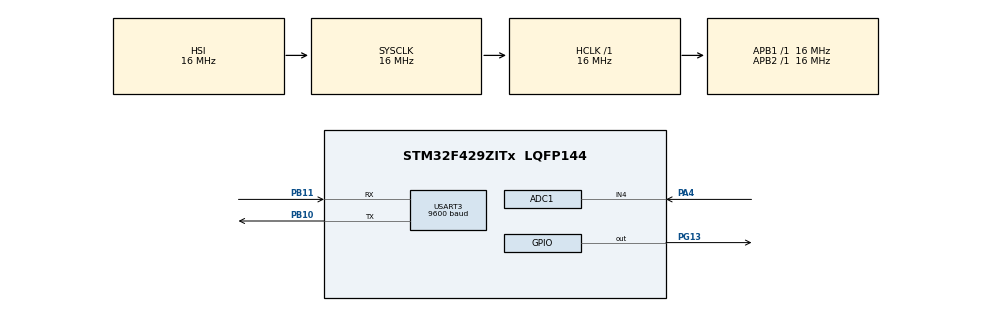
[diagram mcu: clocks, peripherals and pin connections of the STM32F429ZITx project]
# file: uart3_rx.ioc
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ADC1.Channel-0\#ChannelRegularConversion=ADC_CHANNEL_4
ADC1.ContinuousConvMode=ENABLE
ADC1.NbrOfConversionFlag=1
ADC1.Rank-0\#ChannelRegularConversion=1
ADC1.SamplingTime-0\#ChannelRegularConversion=ADC_SAMPLETIME_3CYCLES
ADC1.master=1
Mcu.Family=STM32F4
Mcu.Name=STM32F429ZITx
Mcu.Package=LQFP144
NVIC.PriorityGroup=NVIC_PRIORITYGROUP_4
NVIC.USART3_IRQn=true\:0\:0\:false\:false\:true\:true\:true\:true
PA13.Mode=Serial_Wire
PA13.Signal=SYS_JTMS-SWDIO
PA14.Mode=Serial_Wire
PA14.Signal=SYS_JTCK-SWCLK
PA4.Signal=ADCx_IN4
PB10.Mode=Asynchronous
PB10.Signal=USART3_TX
PB11.Mode=Asynchronous
PB11.Signal=USART3_RX
PG13.Signal=GPIO_Output
PH0/OSC_IN.Mode=HSE-External-Oscillator
PH0/OSC_IN.Signal=RCC_OSC_IN
PH1/OSC_OUT.Mode=HSE-External-Oscillator
PH1/OSC_OUT.Signal=RCC_OSC_OUT
ProjectManager.HeapSize=0x200
ProjectManager.StackSize=0x400
ProjectManager.TargetToolchain=STM32CubeIDE
RCC.AHBFreq_Value=16000000
RCC.APB1Freq_Value=16000000
RCC.APB2Freq_Value=16000000
RCC.CortexFreq_Value=16000000
RCC.HSE_VALUE=25000000
RCC.HSI_VALUE=16000000
RCC.LSE_VALUE=32768
RCC.SYSCLKFreq_VALUE=16000000
RCC.VCOOutputFreq_Value=192000000
SH.ADCx_IN4.0=ADC1_IN4,IN4
USART3.BaudRate=9600
USART3.VirtualMode=VM_ASYNC
board=custom

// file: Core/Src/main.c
/* USER CODE BEGIN Header */
/**
  ******************************************************************************
  * @file           : main.c
  * @brief          : Main program body
  ******************************************************************************
  * @attention
  *
  * Copyright (c) 2024 STMicroelectronics.
  * All rights reserved.
  *
  * This software is licensed under terms that can be found in the LICENSE file
  * in the root directory of this software component.
  * If no LICENSE file comes with this software, it is provided AS-IS.
  *
  ******************************************************************************
  */
/* USER CODE END Header */
#include "main.h"
#include "adc.h"
#include "usart.h"
#include "gpio.h"

/* USER CODE BEGIN Includes */
#include <stdio.h>
#include <string.h>  // 추가: strlen() 함수 사용을 위한 헤더 파일 포함
/* USER CODE END Includes */

/* USER CODE BEGIN PV */
char buffer[10];
/* USER CODE END PV */

void SystemClock_Config(void);

int main(void)
{

  /* MCU Configuration--------------------------------------------------------*/

  /* Reset of all peripherals, Initializes the Flash interface and the Systick. */
  HAL_Init();

  /* Configure the system clock */
  SystemClock_Config();

  /* Initialize all configured peripherals */
  MX_GPIO_Init();
  MX_USART3_UART_Init();
  MX_ADC1_Init();
  /* USER CODE BEGIN 2 */
  int adc_val = 0;
  //uint8_t data;
  /* USER CODE END 2 */

  /* Infinite loop */
  /* USER CODE BEGIN WHILE */
  while (1)
  {
	  /*HAL_UART_Receive(&huart3, &data,sizeof(data),1000);

	  if( data =='a')
	  {
		  HAL_GPIO_WritePin(GPIOG, GPIO_PIN_13, 1);
	  }
	  else if(data  =='b')
	  {
		  HAL_GPIO_WritePin(GPIOG, GPIO_PIN_13, 0);
	  }*/

	  // ADC 변환 시작
	  HAL_ADC_Start(&hadc1);
	  // 변환 완료 대기
	  if (HAL_ADC_PollForConversion(&hadc1, HAL_MAX_DELAY) == HAL_OK) {
	      // 변환된 값을 읽기
	      adc_val = HAL_ADC_GetValue(&hadc1);
	      // UART3를 통해 값 전송 (숫자 값만 보내기)
	      sprintf(buffer, "%d\r\n", adc_val);
	      HAL_UART_Transmit(&huart3, (uint8_t*)buffer, strlen(buffer), 100);
	  }
	  // ADC 변환 종료
	  HAL_ADC_Stop(&hadc1);

	  HAL_Delay(500);
    /* USER CODE END WHILE */

  }
}

void SystemClock_Config(void)
{
  RCC_OscInitTypeDef RCC_OscInitStruct = {0};
  RCC_ClkInitTypeDef RCC_ClkInitStruct = {0};

  /** Configure the main internal regulator output voltage
  */
  __HAL_RCC_PWR_CLK_ENABLE();
  __HAL_PWR_VOLTAGESCALING_CONFIG(PWR_REGULATOR_VOLTAGE_SCALE3);

  /** Initializes the RCC Oscillators according to the specified parameters
  * in the RCC_OscInitTypeDef structure.
  */
  RCC_OscInitStruct.OscillatorType = RCC_OSCILLATORTYPE_HSI;
  RCC_OscInitStruct.HSIState = RCC_HSI_ON;
  RCC_OscInitStruct.HSICalibrationValue = RCC_HSICALIBRATION_DEFAULT;
  RCC_OscInitStruct.PLL.PLLState = RCC_PLL_NONE;
  if (HAL_RCC_OscConfig(&RCC_OscInitStruct) != HAL_OK)
  {
    Error_Handler();
  }

  /** Initializes the CPU, AHB and APB buses clocks
  */
  RCC_ClkInitStruct.ClockType = RCC_CLOCKTYPE_HCLK|RCC_CLOCKTYPE_SYSCLK
                              |RCC_CLOCKTYPE_PCLK1|RCC_CLOCKTYPE_PCLK2;
  RCC_ClkInitStruct.SYSCLKSource = RCC_SYSCLKSOURCE_HSI;
  RCC_ClkInitStruct.AHBCLKDivider = RCC_SYSCLK_DIV1;
  RCC_ClkInitStruct.APB1CLKDivider = RCC_HCLK_DIV1;
  RCC_ClkInitStruct.APB2CLKDivider = RCC_HCLK_DIV1;

  if (HAL_RCC_ClockConfig(&RCC_ClkInitStruct, FLASH_LATENCY_0) != HAL_OK)
  {
    Error_Handler();
  }
}

void Error_Handler(void)
{
  __disable_irq();
  while (1)
  {
  }
}
